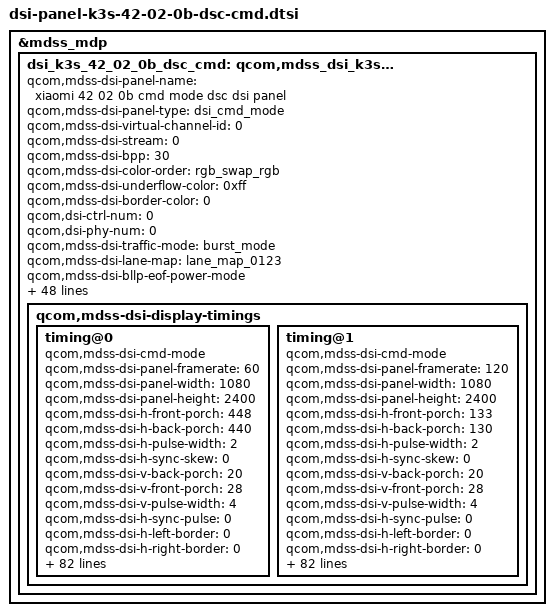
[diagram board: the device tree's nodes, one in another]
&mdss_mdp {
	dsi_k3s_42_02_0b_dsc_cmd: qcom,mdss_dsi_k3s_42_02_0b_dsc_cmd {
		qcom,mdss-dsi-panel-name = "xiaomi 42 02 0b cmd mode dsc dsi panel";
		qcom,mdss-dsi-panel-type = "dsi_cmd_mode";
		qcom,mdss-dsi-virtual-channel-id = <0>;
		qcom,mdss-dsi-stream = <0>;
		qcom,mdss-dsi-bpp = <30>;
		qcom,mdss-dsi-color-order = "rgb_swap_rgb";
		qcom,mdss-dsi-underflow-color = <0xff>;
		qcom,mdss-dsi-border-color = <0>;

		qcom,dsi-ctrl-num = <0>;
		qcom,dsi-phy-num = <0>;

		qcom,mdss-dsi-traffic-mode = "burst_mode";
		qcom,mdss-dsi-lane-map = "lane_map_0123";
		qcom,mdss-dsi-bllp-eof-power-mode;
		qcom,mdss-dsi-bllp-power-mode;
		qcom,mdss-dsi-lane-0-state;
		qcom,mdss-dsi-lane-1-state;
		qcom,mdss-dsi-lane-2-state;
		qcom,mdss-dsi-lane-3-state;
		qcom,mdss-dsi-dma-trigger = "trigger_sw";
		qcom,mdss-dsi-mdp-trigger = "none";
		qcom,mdss-dsi-reset-sequence = <0 10>, <1 10>, <0 1>, <1 10>;
		qcom,mdss-pan-physical-width-dimension = <695>;
		qcom,mdss-pan-physical-height-dimension = <1545>;
		qcom,mdss-dsi-te-pin-select = <1>;
		qcom,mdss-dsi-wr-mem-start = <0x2c>;
		qcom,mdss-dsi-wr-mem-continue = <0x3c>;
		qcom,mdss-dsi-te-dcs-command = <1>;
		qcom,mdss-dsi-te-check-enable;
		qcom,mdss-dsi-te-using-te-pin;
		qcom,mdss-dsi-tx-eot-append;
		qcom,mdss-dsi-lp11-init;

		qcom,mdss-dsi-panel-mode-switch;

		qcom,mdss-dsi-bl-inverted-dbv;
		qcom,bl-update-flag = "delay_until_first_frame";

		qcom,mdss-dsi-panel-hdr-enabled;
		qcom,mdss-dsi-panel-hdr-color-primaries = <14500 15500 32000
			17000 15500 30000 8000 3000>;
		qcom,mdss-dsi-panel-peak-brightness = <4200000>;
		qcom,mdss-dsi-panel-blackness-level = <3230>;

		qcom,mdss-dsi-display-timings {
			timing@0{
				qcom,mdss-dsi-cmd-mode;
				qcom,mdss-dsi-panel-framerate = <60>;
				qcom,mdss-dsi-panel-width = <1080>;
				qcom,mdss-dsi-panel-height = <2400>;
				qcom,mdss-dsi-h-front-porch = <448>;
				qcom,mdss-dsi-h-back-porch = <440>;
				qcom,mdss-dsi-h-pulse-width = <2>;
				qcom,mdss-dsi-h-sync-skew = <0>;
				qcom,mdss-dsi-v-back-porch = <20>;
				qcom,mdss-dsi-v-front-porch = <28>;
				qcom,mdss-dsi-v-pulse-width = <4>;
				qcom,mdss-dsi-h-sync-pulse = <0>;
				qcom,mdss-dsi-h-left-border = <0>;
				qcom,mdss-dsi-h-right-border = <0>;
				qcom,mdss-dsi-v-top-border = <0>;
				qcom,mdss-dsi-v-bottom-border = <0>;
				qcom,mdss-dsi-panel-clockrate = <1100000000>;
				qcom,mdss-dsi-panel-jitter = <0x5 0x1>;
				qcom,mdss-mdp-transfer-time-us = <7000>;
				qcom,mdss-dsi-on-command = [
					39 01 00 00 00 00 06 F0 55 AA 52 08 01
					39 01 00 00 00 00 02 6F 02
					39 01 00 00 00 00 02 D2 00
					//SRE off, VGL pump倍率=AVEE-VDDI
					39 01 00 00 00 00 06 F0 55 AA 52 08 01
					39 01 00 00 00 00 02 6F 08
					39 01 00 00 00 00 05 B4 00 00 00 00
					39 01 00 00 00 00 05 B2 AA 02 55 01
					// fix aod flash
					39 01 00 00 00 00 06 F0 55 AA 52 08 01
					39 01 00 00 00 00 02 6F 01
					39 01 00 00 00 00 02 D2 2A
					//Source Rising/Falling Time Strong
					39 01 00 00 00 00 05 FF AA 55 A5 80
					39 01 00 00 00 00 02 6F 1B
					39 01 00 00 00 00 02 F4 55
					/* ESD */
					39 01 00 00 00 00 06 F0 55 AA 52 08 00
					39 01 00 00 00 00 02 6F 05
					39 01 00 00 00 00 02 BE 08
					39 01 00 00 00 00 02 6F 01
					39 01 00 00 00 00 02 BE 45
					/* Round ON */
					39 01 00 00 00 00 06 F0 55 AA 52 08 07
					39 01 00 00 00 00 02 C0 B1
					/* Open Video Trim*/
					39 01 00 00 00 00 06 F0 55 AA 52 08 01
					39 01 00 00 00 00 02 CD 61
					/* DC init Code */
					// Add DC 20210913
					//ADD initial cdoe
					39 01 00 00 00 00 06 F0 55 AA 52 08 00
					//REMAP_RATIO_00~REMAP_RATIO_34
					39 01 00 00 00 00 02 6F 2B
					39 01 00 00 00 00 47 B2
						00 00 02 FD 04 19 05 49 05 EC 06 7D 07 3E 07 B2
						08 52 08 B5 09 13 09 98 09 ED 0A 3D 0A B2 0A FC
						0B 44 0B AC 0B EF 0C 50 0C 8F 0C CD 0D 26 0D 61
						0D 9A 0D ED 0E 24 0E 59 0E A8 0E DB 0F 26 0F 58
						0F 88 0F D0 0F FF
					//REMAP_DBV_TH_00~REMAP_DBV_TH_33
					39 01 00 00 00 00 02 6F 34
					39 01 00 00 00 00 45 B3
						00 08 00 12 00 1B 00 25 00 2F 00 38 00 42 00 4C
						00 55 00 5F 00 69 00 72 00 7C 00 86 00 8F 00 99
						00 A3 00 AC 00 B6 00 C0 00 C9 00 D3 00 DD 00 E6
						00 F0 00 FA 01 03 01 0D 01 17 01 20 01 2A 01 34
						01 3D 01 47

					/* 3.1 DVDD Strong */
					39 01 00 00 00 00 06 F0 55 AA 52 08 01
					39 01 00 00 00 00 05 C5 00 0B 0B 0B
					/* DSC Setting */
					39 01 00 00 00 00 03 90 13 03
					39 01 00 00 00 00 13 91 AB 28 00 0C D2 00 03 49 01 69 00 0F 09 75 04 3D 10 F0
					//39 01 00 00 00 00 13 91 AB A8 00 0C C2 00 03 1C 01 7E 00 0F 08 BB 04 3D 10 F0
					39 01 00 00 00 00 02 1F 70
					/* 3.2 TE ON */
					39 01 00 00 00 00 02 35 00
					39 01 00 00 00 00 02 5A 01
					/* 3.3 CASET/RASET Setting */
					39 01 00 00 00 00 05 2A 00 00 04 37                  /* CASET 1080 */
					39 01 00 00 00 00 05 2B 00 00 09 5F                  /* PASET 2400 */
					/* 3.4 Dimming  ON Setting */
					39 01 00 00 00 00 02 53 28
					/* 3.4.1 Adjusting dimming speed */
					39 00 00 00 00 00 06 F0 55 AA 52 08 00
					39 00 00 00 00 00 02 B2 09
					39 00 00 00 00 00 02 6F 05
					39 01 00 00 00 00 03 B2 08 08
					/* 3.5 Frame Rate 60Hz GIR OFF*/
					39 01 00 00 00 00 02 2F 02
					/* 3.6 GIR OFF */
					39 01 00 00 00 00 02 5F 01
					/* 3.7 DBV */
					//39 01 00 00 00 00 03 51 07 FF
					/* 4. User Command Set */
					/* Sleep Out */
					39 01 00 00 78 00 02 11 00
					/* Display On */
					39 01 00 00 00 00 02 29 00
					];
				qcom,mdss-dsi-on-command-state = "dsi_lp_mode";
				qcom,mdss-dsi-off-command = [
					39 01 00 00 00 00 02 28 00
					39 01 00 00 64 00 02 10 00];
				qcom,mdss-dsi-off-command-state = "dsi_lp_mode";

				qcom,mdss-dsi-timing-switch-command = [
					/* Frame Rate 60Hz GIR OFF*/
					39 00 00 00 00 00 02 2F 02
					39 01 00 00 00 00 02 5F 01
				];
				qcom,mdss-dsi-timing-switch-command-state = "dsi_hs_mode";

				qcom,mdss-dsi-nolp-command = [
					39 00 00 00 00 00 07 51 00 00 00 00 00 00
					/* AOD off */
					39 00 00 00 00 00 02 65 00
					39 00 00 00 00 00 02 38 00
					39 00 00 00 00 00 06 F0 55 AA 52 08 00
					39 00 00 00 00 00 02 6F 05
					39 01 00 00 00 00 02 BE 08
				];
				qcom,mdss-dsi-nolp-command-state = "dsi_lp_mode";

				qcom,compression-mode = "dsc";
				qcom,mdss-dsc-version = <0x12>;
				qcom,mdss-dsc-scr-version = <0x0>;
				qcom,mdss-dsc-slice-height = <12>;
				qcom,mdss-dsc-slice-width = <1080>;
				qcom,mdss-dsc-slice-per-pkt = <2>;
				qcom,mdss-dsc-bit-per-component = <10>;
				qcom,mdss-dsc-bit-per-pixel = <8>;
				qcom,mdss-dsc-block-prediction-enable;
			};
			timing@1{
				qcom,mdss-dsi-cmd-mode;
				qcom,mdss-dsi-panel-framerate = <120>;
				qcom,mdss-dsi-panel-width = <1080>;
				qcom,mdss-dsi-panel-height = <2400>;
				qcom,mdss-dsi-h-front-porch = <133>;
				qcom,mdss-dsi-h-back-porch = <130>;
				qcom,mdss-dsi-h-pulse-width = <2>;
				qcom,mdss-dsi-h-sync-skew = <0>;
				qcom,mdss-dsi-v-back-porch = <20>;
				qcom,mdss-dsi-v-front-porch = <28>;
				qcom,mdss-dsi-v-pulse-width = <4>;
				qcom,mdss-dsi-h-sync-pulse = <0>;
				qcom,mdss-dsi-h-left-border = <0>;
				qcom,mdss-dsi-h-right-border = <0>;
				qcom,mdss-dsi-v-top-border = <0>;
				qcom,mdss-dsi-v-bottom-border = <0>;
				qcom,mdss-dsi-panel-clockrate = <1100000000>;
				qcom,mdss-dsi-panel-jitter = <0x5 0x1>;
				qcom,mdss-mdp-transfer-time-us = <7000>;
				qcom,mdss-dsi-on-command = [
					39 01 00 00 00 00 06 F0 55 AA 52 08 01
					39 01 00 00 00 00 02 6F 02
					39 01 00 00 00 00 02 D2 00
					//SRE off, VGL pump倍率=AVEE-VDDI
					39 01 00 00 00 00 06 F0 55 AA 52 08 01
					39 01 00 00 00 00 02 6F 08
					39 01 00 00 00 00 05 B4 00 00 00 00
					39 01 00 00 00 00 05 B2 AA 02 55 01
					// fix aod flash
					39 01 00 00 00 00 06 F0 55 AA 52 08 01
					39 01 00 00 00 00 02 6F 01
					39 01 00 00 00 00 02 D2 2A
					//Source Rising/Falling Time Strong
					39 01 00 00 00 00 05 FF AA 55 A5 80
					39 01 00 00 00 00 02 6F 1B
					39 01 00 00 00 00 02 F4 55
					/* ESD */
					39 01 00 00 00 00 06 F0 55 AA 52 08 00
					39 01 00 00 00 00 02 6F 05
					39 01 00 00 00 00 02 BE 08
					39 01 00 00 00 00 02 6F 01
					39 01 00 00 00 00 02 BE 45
					/* Round ON */
					39 01 00 00 00 00 06 F0 55 AA 52 08 07
					39 01 00 00 00 00 02 C0 B1
					/* Open Video Trim*/
					39 01 00 00 00 00 06 F0 55 AA 52 08 01
					39 01 00 00 00 00 02 CD 61
					/* DC init Code */
					// Add DC 20210913
					//ADD initial cdoe
					39 01 00 00 00 00 06 F0 55 AA 52 08 00
					//REMAP_RATIO_00~REMAP_RATIO_34
					39 01 00 00 00 00 02 6F 2B
					39 01 00 00 00 00 47 B2
						00 00 02 FD 04 19 05 49 05 EC 06 7D 07 3E 07 B2
						08 52 08 B5 09 13 09 98 09 ED 0A 3D 0A B2 0A FC
						0B 44 0B AC 0B EF 0C 50 0C 8F 0C CD 0D 26 0D 61
						0D 9A 0D ED 0E 24 0E 59 0E A8 0E DB 0F 26 0F 58
						0F 88 0F D0 0F FF
					//REMAP_DBV_TH_00~REMAP_DBV_TH_33
					39 01 00 00 00 00 02 6F 34
					39 01 00 00 00 00 45 B3
						00 08 00 12 00 1B 00 25 00 2F 00 38 00 42 00 4C
						00 55 00 5F 00 69 00 72 00 7C 00 86 00 8F 00 99
						00 A3 00 AC 00 B6 00 C0 00 C9 00 D3 00 DD 00 E6
						00 F0 00 FA 01 03 01 0D 01 17 01 20 01 2A 01 34
						01 3D 01 47

					/* 3.1 DVDD Strong */
					39 01 00 00 00 00 06 F0 55 AA 52 08 01
					39 01 00 00 00 00 05 C5 00 0B 0B 0B
					/* DSC Setting */
					39 01 00 00 00 00 03 90 13 03
					39 01 00 00 00 00 13 91 AB 28 00 0C C2 00 03 1C 01 7E 00 0F 08 BB 04 3D 10 F0
					39 01 00 00 00 00 02 1F 70
					/* 3.2 TE ON */
					39 01 00 00 00 00 02 35 00
					39 01 00 00 00 00 02 5A 01
					/* 3.3 CASET/RASET Setting */
					39 01 00 00 00 00 05 2A 00 00 04 37                  /* CASET 1080 */
					39 01 00 00 00 00 05 2B 00 00 09 5F                  /* PASET 2400 */
					/* 3.4 Dimming  ON Setting */
					39 01 00 00 00 00 02 53 28
					/* 3.4.1 Adjusting dimming speed */
					39 00 00 00 00 00 06 F0 55 AA 52 08 00
					39 00 00 00 00 00 02 B2 09
					39 00 00 00 00 00 02 6F 05
					39 01 00 00 00 00 03 B2 08 08
					/* 3.5 Frame Rate 120Hz GIR OFF*/
					39 01 00 00 00 00 02 2F 00
					39 01 00 00 00 00 02 26 00
					/* 3.6 GIR OFF */
					39 01 00 00 00 00 02 5F 01
					/* 3.7 DBV */
					//39 01 00 00 00 00 03 51 07 FF
					/* 4. User Command Set */
					/* Sleep Out */
					39 01 00 00 78 00 02 11 00
					/* Display On */
					39 01 00 00 00 00 02 29 00];
				qcom,mdss-dsi-on-command-state = "dsi_lp_mode";
				qcom,mdss-dsi-off-command = [
					39 01 00 00 00 00 02 28 00
					39 01 00 00 64 00 02 10 00];
				qcom,mdss-dsi-off-command-state = "dsi_lp_mode";

				qcom,mdss-dsi-timing-switch-command = [
					/* Frame Rate 120Hz GIR OFF*/
					39 00 00 00 00 00 02 2F 00
					39 00 00 00 00 00 02 26 00
					39 01 00 00 00 00 02 5F 01
				];
				qcom,mdss-dsi-timing-switch-command-state = "dsi_hs_mode";

				qcom,mdss-dsi-nolp-command = [
					39 00 00 00 00 00 07 51 00 00 00 00 00 00
					/* AOD off */
					39 00 00 00 00 00 02 65 00
					39 00 00 00 00 00 02 38 00
					39 00 00 00 00 00 06 F0 55 AA 52 08 00
					39 00 00 00 00 00 02 6F 05
					39 01 00 00 00 00 02 BE 08
				];
				qcom,mdss-dsi-nolp-command-state = "dsi_lp_mode";

				qcom,compression-mode = "dsc";
				qcom,mdss-dsc-version = <0x12>;
				qcom,mdss-dsc-scr-version = <0x0>;
				qcom,mdss-dsc-slice-height = <12>;
				qcom,mdss-dsc-slice-width = <1080>;
				qcom,mdss-dsc-slice-per-pkt = <2>;
				qcom,mdss-dsc-bit-per-component = <10>;
				qcom,mdss-dsc-bit-per-pixel = <8>;
				qcom,mdss-dsc-block-prediction-enable;
			};
		};
	};
};

&dsi_k3s_42_02_0b_dsc_cmd {
	mi,panel-id = <0x004B3353 0x00420200>;
	mi,hbm-51-ctl-flag;
	mi,hbm-off-51-index = <0>;
	mi,hbm-on-51-index = <0>;
	mi,hbm-bl-min-level = <1>;
	mi,hbm-bl-max-level = <2047>;
	mi,max-brightness-clone = <8191>;
	mi,fp-display-on-optimize-flag;
	mi,panel-aod-to-off-command-need-enabled;

	mi,dc-sync-te-flag;
	mi,mdss-dsi-panel-dc-type = <0>;
	mi,dc-update-flag;
	mi,dc-gain-type = <1>;
	mi,dc-on-120hz-d2-index = <10>;
	mi,dc-off-120hz-d2-index = <10>;
	mi,dc-on-60hz-d4-index = <11>;
	mi,dc-off-60hz-d4-index = <11>;
//	mi,flatmode-update-flag;
//	mi,flatmode-on-b9-index = <3>;

	/* IRQF_ONESHOT | IRQF_TRIGGER_RISING */
	mi,esd-err-irq-gpio = <&tlmm 75 0x2001>;
	qcom,esd-check-enabled;
	qcom,esd-aod-check-enabled;
/*	qcom,mdss-dsi-panel-status-check-mode = "reg_read";
	qcom,mdss-dsi-panel-status-offset-command = [
		39 01 00 00 00 00 05 FF AA 55 A5 81
		39 01 00 00 00 00 02 6F 0F];
	qcom,mdss-dsi-panel-status-command = [
		06 01 00 01 00 00 01 FA
		06 01 00 01 00 00 01 91];
	qcom,mdss-dsi-panel-status-read-length = <1 18>;
	qcom,mdss-dsi-panel-max-error-count = <3>;
	qcom,mdss-dsi-panel-status-value =
		<0x00>,
		<0xAB 0xA8 0x00 0x0C 0xC2 0x00 0x03 0x1C 0x01 0x7E 0x00 0x0F 0x08 0xBB 0x04 0x3D 0x10 0xF0>;
	qcom,mdss-dsi-panel-status-command-state = "dsi_lp_mode";
	qcom,mdss-dsi-panel-status-offset-command-state = "dsi_lp_mode";
*/
	mi,panel-on-dimming-delay = <120>;

	//mi,mdss-dsi-panel-dc-threshold = <450>;
	// mi,mdss-dsi-panel-hbm-brightness = <1>;

	qcom,mdss-dsi-display-timings {
		timing@0 {
			mi,mdss-dsc-panel-id = <0x004B3353 0x00420200>;
			mi,mdss-dsi-dimmingon-command = [
			39 01 00 00 00 00 02 53 28];
			mi,mdss-dsi-dimmingon-command-state = "dsi_hs_mode";
			mi,mdss-dsi-dimmingoff-command = [39 01 00 00 00 00 02 53 20];
			mi,mdss-dsi-dimmingoff-command-state = "dsi_hs_mode";
			mi,mdss-dsi-hbm-on-command = [39 01 00 00 00 00 03 51 0F FF];
			mi,mdss-dsi-hbm-on-command-state = "dsi_lp_mode";
			mi,mdss-dsi-hbm-off-command = [39 01 00 00 00 00 03 51 07 FF];
			mi,mdss-dsi-hbm-off-command-state = "dsi_lp_mode";

			mi,aod-hbm-51-index = <13>;
			mi,aod-lbm-51-index = <13>;

			mi,mdss-dsi-doze-hbm-command = [
				39 00 00 00 00 00 06 F0 55 AA 52 08 00
				39 00 00 00 00 00 02 6F 05
				39 00 00 00 00 00 02 BE 00
				39 00 00 00 00 00 02 39 00
				39 00 00 00 00 00 02 65 01
				39 01 00 00 00 00 07 51 01 06 00 00 0F FF
			];
			mi,mdss-dsi-doze-hbm-command-state = "dsi_lp_mode";
			mi,mdss-dsi-doze-lbm-command = [
				39 00 00 00 00 00 06 F0 55 AA 52 08 00
				39 00 00 00 00 00 02 6F 05
				39 00 00 00 00 00 02 BE 00
				39 00 00 00 00 00 02 39 00
				39 00 00 00 00 00 02 65 01
				39 01 00 00 00 00 07 51 00 24 00 00 01 55
			];
			mi,mdss-dsi-doze-lbm-command-state = "dsi_lp_mode";

			mi,mdss-dsi-pre-doze-to-off-command = [
				39 00 00 00 00 00 06 F0 55 AA 52 08 01
				39 00 00 00 00 00 02 6F 02
				39 00 00 00 00 00 02 B0 00
				39 00 00 00 00 00 02 E4 90
				39 00 00 00 00 00 02 6F 0A
				39 01 00 00 00 00 02 E4 90
				39 01 00 00 00 00 02 28 00
				39 01 00 00 64 00 02 10 00];
			mi,mdss-dsi-pre-doze-to-off-command-state = "dsi_lp_mode";

			mi,mdss-dsi-switch-page4-command = [
				/* Set page 4 */
				39 01 00 00 00 00 06 F0 55 AA 52 08 04];
			mi,mdss-dsi-switch-page4-command-state = "dsi_lp_mode";

			mi,mdss-dsi-dc-on-command = [
				39 00 00 00 00 00 06 F0 55 AA 52 08 00
				39 00 00 00 00 00 02 6F 18
				39 00 00 00 00 00 03 B2 00 00
				39 00 00 00 00 00 2D B3
					00 00 00 00 00 00 00 00 00 00 00 00 00 00 00 00
					00 00 00 00 00 00 00 00 01 47 02 F5 02 F5 04 A3
					04 A3 06 51 06 51 07 FF 07 FF 0F FF
				39 00 00 00 00 00 04 B2 89 87 3F
				39 00 00 00 00 00 06 F0 55 AA 52 08 02
				39 00 00 00 00 00 02 CC 30
				39 01 00 00 14 00 02 CE 01
				39 01 00 00 00 00 02 CC 00

				/* Set page 4 */
				39 00 00 00 00 00 06 F0 55 AA 52 08 04
				/* Enter_DC_LUT @ 120Hz */
				/* need read 0xD2 to update */
				39 01 00 00 00 00 4C D2
					00 00 00 00 00 00 00 00 00 00 00 00 00 00 00 00
					00 00 00 00 00 00 00 00 00 00 00 00 00 00 00 00
					00 00 00 00 00 00 00 00 00 00 00 00 00 00 00 00
					00 00 00 00 00 00 00 00 00 00 00 00 00 00 00 00
					00 00 00 00 00 00 00 00 00 00 00
				/* Enter_DC_LUT @ 60Hz */
				/* need read 0xD4 to update */
				39 01 00 00 00 00 4C D4
					00 00 00 00 00 00 00 00 00 00 00 00 00 00 00 00
					00 00 00 00 00 00 00 00 00 00 00 00 00 00 00 00
					00 00 00 00 00 00 00 00 00 00 00 00 00 00 00 00
					00 00 00 00 00 00 00 00 00 00 00 00 00 00 00 00
					00 00 00 00 00 00 00 00 00 00 00
			];
			mi,mdss-dsi-dc-on-command-state = "dsi_hs_mode";
			mi,mdss-dsi-dc-off-command = [
				39 00 00 00 00 00 06 F0 55 AA 52 08 00
				39 00 00 00 00 00 02 6F 18
				39 00 00 00 00 00 03 B2 05 18
				39 00 00 00 00 00 2D B3
					00 08 00 18 00 18 00 31 00 31 00 62 00 62 00 C0
					00 C0 01 46 01 46 01 47 01 47 02 F5 02 F5 04 A3
					04 A3 06 51 06 51 07 FF 07 FF 0F FF
				39 00 00 00 00 00 04 B2 09 00 00
				39 00 00 00 00 00 06 F0 55 AA 52 08 02
				39 00 00 00 00 00 02 CC 30
				39 01 00 00 14 00 02 CE 01
				39 01 00 00 00 00 02 CC 00

				/* Set page 4 */
				39 00 00 00 00 00 06 F0 55 AA 52 08 04
				/* Exit_DC_LUT @ 120Hz */
				/* Use the read 0xD2 parameters(Driver IC OTP) */
				39 01 00 00 00 00 4C D2
					00 00 00 00 00 00 00 00 00 00 00 00 00 00 00 00
					00 00 00 00 00 00 00 00 00 00 00 00 00 00 00 00
					00 00 00 00 00 00 00 00 00 00 00 00 00 00 00 00
					00 00 00 00 00 00 00 00 00 00 00 00 00 00 00 00
					00 00 00 00 00 00 00 00 00 00 00
				/* Exit_DC_LUT @ 60Hz */
				/* Use the read 0xD4 parameters(Driver IC OTP) */
				39 01 00 00 00 00 4C D4
					00 00 00 00 00 00 00 00 00 00 00 00 00 00 00 00
					00 00 00 00 00 00 00 00 00 00 00 00 00 00 00 00
					00 00 00 00 00 00 00 00 00 00 00 00 00 00 00 00
					00 00 00 00 00 00 00 00 00 00 00 00 00 00 00 00
					00 00 00 00 00 00 00 00 00 00 00
			];
			mi,mdss-dsi-dc-off-command-state = "dsi_hs_mode";

			mi,mdss-dsi-flat-mode-on-command = [
				/* GIR ON , 60Hz */
				39 00 00 00 00 00 02 2F 03
				39 01 00 00 00 00 02 5F 00];
			mi,mdss-dsi-flat-mode-on-command-state = "dsi_hs_mode";
			mi,mdss-dsi-flat-mode-off-command = [
				/* GIR OFF , 60Hz */
				39 00 00 00 00 00 02 2F 02
				39 01 00 00 00 00 02 5F 01];
			mi,mdss-dsi-flat-mode-off-command-state = "dsi_hs_mode";

			mi,mdss-dsi-timing-switch-gir-command = [
				/* Frame Rate 60Hz GIR ON */
				39 00 00 00 00 00 02 2F 03
				39 01 00 00 00 00 02 5F 00
			];
			mi,mdss-dsi-timing-switch-gir-command-state = "dsi_hs_mode";

			mi,mdss-dsi-aod-to-dc-on-command = [
				39 00 00 00 00 00 06 F0 55 AA 52 08 00
				39 01 00 00 00 00 02 B2 89];
			mi,mdss-dsi-aod-to-dc-on-command-state = "dsi_hs_mode";
		};
		timing@1 {
			mi,mdss-dsc-panel-id = <0x004B3353 0x00420200>;
			mi,mdss-dsi-dimmingon-command = [
			39 01 00 00 00 00 02 53 28];
			mi,mdss-dsi-dimmingon-command-state = "dsi_hs_mode";
			mi,mdss-dsi-dimmingoff-command = [39 01 00 00 00 00 02 53 20];
			mi,mdss-dsi-dimmingoff-command-state = "dsi_hs_mode";

			mi,mdss-dsi-hbm-on-command = [39 01 00 00 00 00 03 51 0F FF];
			mi,mdss-dsi-hbm-on-command-state = "dsi_lp_mode";
			mi,mdss-dsi-hbm-off-command = [39 01 00 00 00 00 03 51 07 FF];
			mi,mdss-dsi-hbm-off-command-state = "dsi_lp_mode";

			mi,aod-hbm-51-index = <15>;
			mi,aod-lbm-51-index = <15>;

			mi,mdss-dsi-doze-hbm-command = [
				39 00 00 00 00 00 06 F0 55 AA 52 08 00
				39 00 00 00 00 00 02 6F 05
				39 00 00 00 00 00 02 BE 00
				39 00 00 00 00 00 02 39 00
				39 00 00 00 00 00 02 65 01
				39 01 00 00 00 00 07 51 01 06 00 00 0F FF
			];
			mi,mdss-dsi-doze-hbm-command-state = "dsi_lp_mode";
			mi,mdss-dsi-doze-lbm-command = [
				39 00 00 00 00 00 06 F0 55 AA 52 08 00
				39 00 00 00 00 00 02 6F 05
				39 00 00 00 00 00 02 BE 00
				39 00 00 00 00 00 02 39 00
				39 00 00 00 00 00 02 65 01
				39 01 00 00 00 00 07 51 00 24 00 00 01 55
			];
			mi,mdss-dsi-doze-lbm-command-state = "dsi_lp_mode";

			mi,mdss-dsi-pre-doze-to-off-command = [
				39 00 00 00 00 00 06 F0 55 AA 52 08 01
				39 00 00 00 00 00 02 6F 02
				39 00 00 00 00 00 02 B0 00
				39 00 00 00 00 00 02 E4 90
				39 00 00 00 00 00 02 6F 0A
				39 01 00 00 00 00 02 E4 90
				39 01 00 00 00 00 02 28 00
				39 01 00 00 64 00 02 10 00];
			mi,mdss-dsi-pre-doze-to-off-command-state = "dsi_lp_mode";

			mi,mdss-dsi-switch-page4-command = [
				/* Set page 4 */
				39 01 00 00 00 00 06 F0 55 AA 52 08 04];
			mi,mdss-dsi-switch-page4-command-state = "dsi_lp_mode";
			mi,mdss-dsi-dc-on-command = [
				// Remapping in
				39 00 00 00 00 00 06 F0 55 AA 52 08 00
				39 00 00 00 00 00 02 6F 18
				39 00 00 00 00 00 03 B2 00 00
				//DBV_TH
				39 00 00 00 00 00 19 B3
					00 00 00 00 00 00 00 00 00 00 00 00 00 00 00 00
					00 00 00 00 00 00 00 00
				39 00 00 00 00 00 04 B2 89 87 3F
				39 00 00 00 00 00 06 F0 55 AA 52 08 02
				39 00 00 00 00 00 02 CC 30
				39 01 00 00 14 00 02 CE 01
				39 01 00 00 00 00 02 CC 00

				/* Set page 4 */
				39 00 00 00 00 00 06 F0 55 AA 52 08 04
				/* Enter_DC_LUT @ 120Hz */
				/* need read 0xD2 to update */
				39 01 00 00 00 00 4C D2
					00 00 00 00 00 00 00 00 00 00 00 00 00 00 00 00
					00 00 00 00 00 00 00 00 00 00 00 00 00 00 00 00
					00 00 00 00 00 00 00 00 00 00 00 00 00 00 00 00
					00 00 00 00 00 00 00 00 00 00 00 00 00 00 00 00
					00 00 00 00 00 00 00 00 00 00 00
				/* Enter_DC_LUT @ 60Hz */
				/* need read 0xD4 to update */
				39 01 00 00 00 00 4C D4
					00 00 00 00 00 00 00 00 00 00 00 00 00 00 00 00
					00 00 00 00 00 00 00 00 00 00 00 00 00 00 00 00
					00 00 00 00 00 00 00 00 00 00 00 00 00 00 00 00
					00 00 00 00 00 00 00 00 00 00 00 00 00 00 00 00
					00 00 00 00 00 00 00 00 00 00 00
			];
			mi,mdss-dsi-dc-on-command-state = "dsi_lp_mode";
			mi,mdss-dsi-dc-off-command = [
				//Remapping out
				39 00 00 00 00 00 06 F0 55 AA 52 08 00
				//EM Pulse number setting
				39 00 00 00 00 00 02 6F 18
				39 00 00 00 00 00 03 B2 05 18
				//DBV_TH
				39 00 00 00 00 00 19 B3
					00 08 00 18 00 18 00 31 00 31 00 62 00 62 00 C0
					00 C0 01 46 01 46 01 47
				39 00 00 00 00 00 04 B2 09 00 00
				39 00 00 00 00 00 06 F0 55 AA 52 08 02
				39 00 00 00 00 00 02 CC 30
				39 01 00 00 14 00 02 CE 01
				39 01 00 00 00 00 02 CC 00

				/* Set page 4 */
				39 00 00 00 00 00 06 F0 55 AA 52 08 04
				/* Exit_DC_LUT @ 120Hz */
				/* Use the read 0xD2 parameters(Driver IC OTP) */
				39 01 00 00 00 00 4C D2
					00 00 00 00 00 00 00 00 00 00 00 00 00 00 00 00
					00 00 00 00 00 00 00 00 00 00 00 00 00 00 00 00
					00 00 00 00 00 00 00 00 00 00 00 00 00 00 00 00
					00 00 00 00 00 00 00 00 00 00 00 00 00 00 00 00
					00 00 00 00 00 00 00 00 00 00 00
				/* Exit_DC_LUT @ 60Hz */
				/* Use the read 0xD4 parameters(Driver IC OTP) */
				39 01 00 00 00 00 4C D4
					00 00 00 00 00 00 00 00 00 00 00 00 00 00 00 00
					00 00 00 00 00 00 00 00 00 00 00 00 00 00 00 00
					00 00 00 00 00 00 00 00 00 00 00 00 00 00 00 00
					00 00 00 00 00 00 00 00 00 00 00 00 00 00 00 00
					00 00 00 00 00 00 00 00 00 00 00
			];
			mi,mdss-dsi-dc-off-command-state = "dsi_hs_mode";

			mi,mdss-dsi-flat-mode-on-command = [
				/* GIR ON , 120Hz */
				39 00 00 00 00 00 02 2F 01
				39 01 00 00 00 00 02 5F 00];
			mi,mdss-dsi-flat-mode-on-command-state = "dsi_hs_mode";
			mi,mdss-dsi-flat-mode-off-command = [
				/* GIR OFF , 120Hz */
				39 00 00 00 00 00 02 2F 00
				39 01 00 00 00 00 02 5F 01];
			mi,mdss-dsi-flat-mode-off-command-state = "dsi_hs_mode";

			mi,mdss-dsi-timing-switch-gir-command = [
				/* Frame Rate 120Hz GIR ON */
				39 00 00 00 00 00 02 2F 01
				39 01 00 00 00 00 02 5F 00
			];
			mi,mdss-dsi-timing-switch-gir-command-state = "dsi_hs_mode";

			mi,mdss-dsi-aod-to-dc-on-command = [
				39 00 00 00 00 00 06 F0 55 AA 52 08 00
				39 01 00 00 00 00 02 B2 89];
			mi,mdss-dsi-aod-to-dc-on-command-state = "dsi_hs_mode";
		};
	};
};
